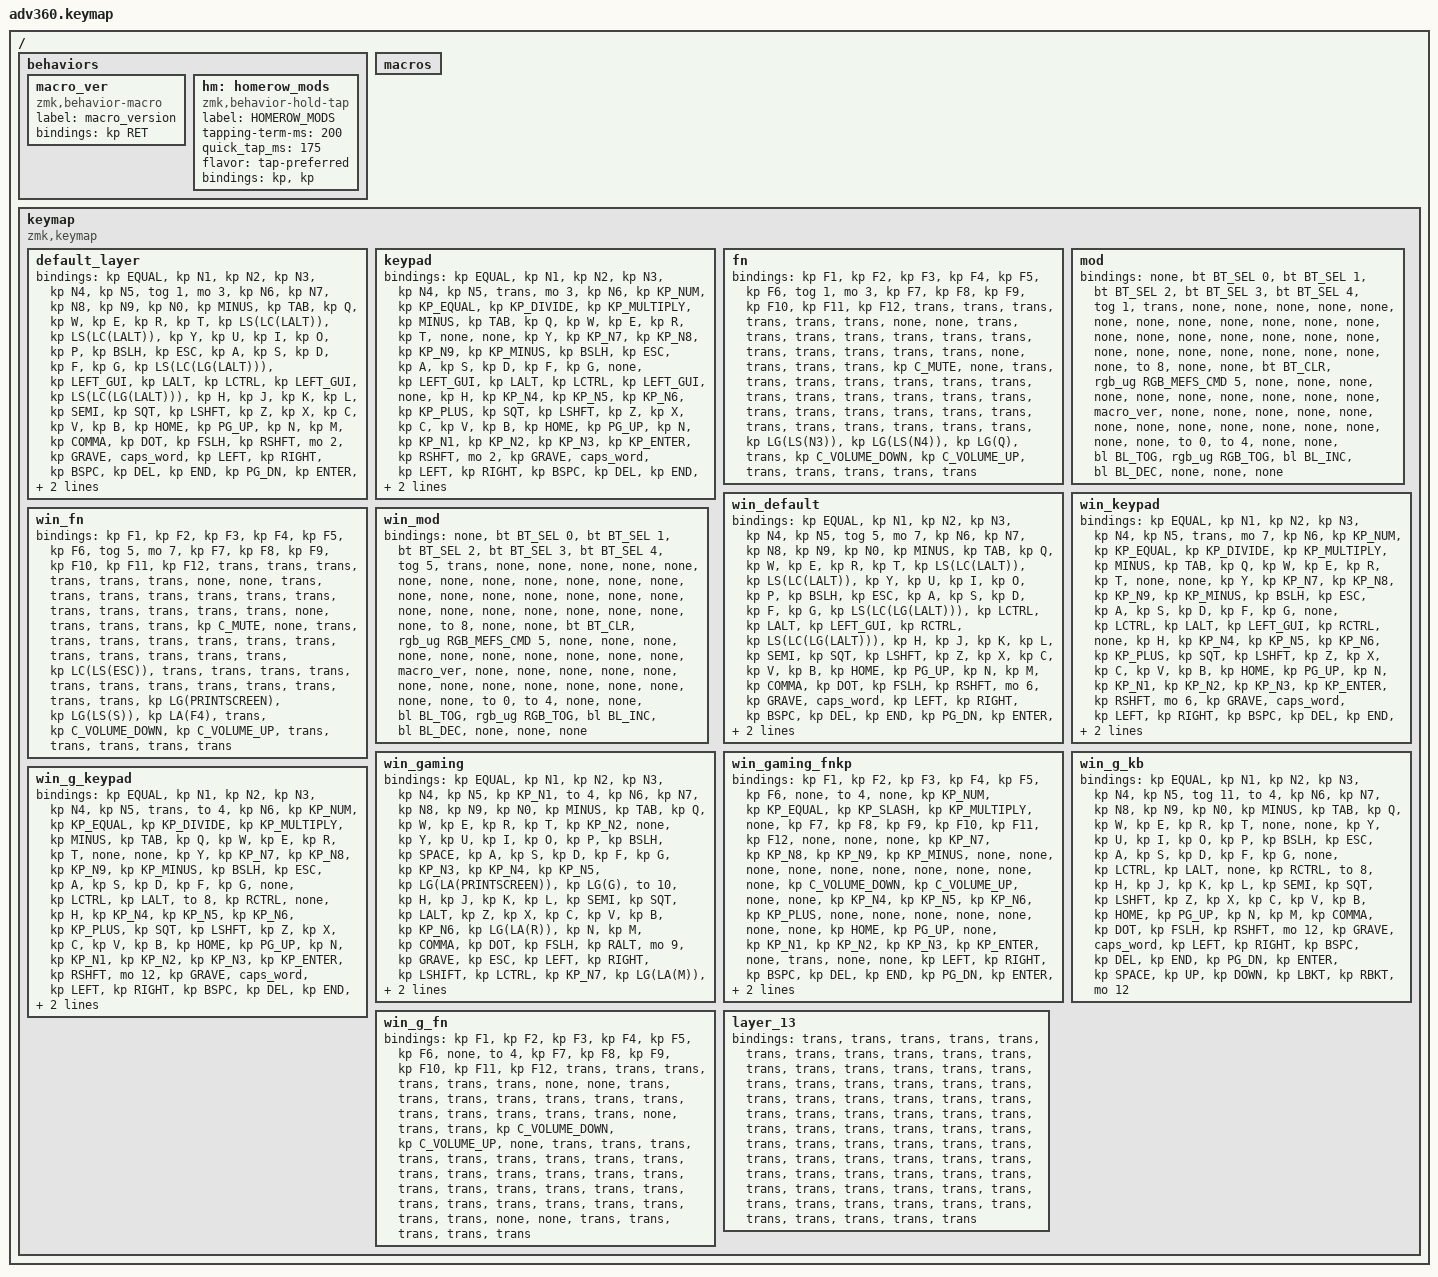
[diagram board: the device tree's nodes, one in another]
#include <behaviors.dtsi>
#include <dt-bindings/zmk/backlight.h>
#include <dt-bindings/zmk/bt.h>
#include <dt-bindings/zmk/keys.h>
#include <dt-bindings/zmk/rgb.h>

/ {
    behaviors {
        #include "macros.dtsi"
      #include "version.dtsi"
      #ifndef VERSION_MACRO

        macro_ver: macro_ver {
            compatible = "zmk,behavior-macro";
            label = "macro_version";
            #binding-cells = <0>;
            bindings = <&kp RET>;
        };

        #endif

        hm: homerow_mods {
            compatible = "zmk,behavior-hold-tap";
            label = "HOMEROW_MODS";
            #binding-cells = <2>;
            tapping-term-ms = <200>;
            quick_tap_ms = <175>;
            flavor = "tap-preferred";
            bindings = <&kp>, <&kp>;
        };
    };

    macros {
    };

    keymap {
        compatible = "zmk,keymap";

        default_layer {
            bindings = <
&kp EQUAL  &kp N1     &kp N2      &kp N3    &kp N4     &kp N5  &tog 1                                                                     &mo 3                 &kp N6  &kp N7  &kp N8     &kp N9    &kp N0    &kp MINUS
&kp TAB    &kp Q      &kp W       &kp E     &kp R      &kp T   &kp LS(LC(LALT))                                                           &kp LS(LC(LALT))      &kp Y   &kp U   &kp I      &kp O     &kp P     &kp BSLH
&kp ESC    &kp A      &kp S       &kp D     &kp F      &kp G   &kp LS(LC(LG(LALT)))  &kp LEFT_GUI  &kp LALT      &kp LCTRL  &kp LEFT_GUI  &kp LS(LC(LG(LALT)))  &kp H   &kp J   &kp K      &kp L     &kp SEMI  &kp SQT
&kp LSHFT  &kp Z      &kp X       &kp C     &kp V      &kp B                                       &kp HOME      &kp PG_UP                                      &kp N   &kp M   &kp COMMA  &kp DOT   &kp FSLH  &kp RSHFT
&mo 2      &kp GRAVE  &caps_word  &kp LEFT  &kp RIGHT          &kp BSPC              &kp DEL       &kp END       &kp PG_DN  &kp ENTER     &kp SPACE                     &kp UP  &kp DOWN   &kp LBKT  &kp RBKT  &mo 2
            >;
        };

        keypad {
            bindings = <
&kp EQUAL  &kp N1     &kp N2      &kp N3    &kp N4     &kp N5  &trans                                                         &mo 3      &kp N6  &kp KP_NUM  &kp KP_EQUAL  &kp KP_DIVIDE  &kp KP_MULTIPLY  &kp MINUS
&kp TAB    &kp Q      &kp W       &kp E     &kp R      &kp T   &none                                                          &none      &kp Y   &kp KP_N7   &kp KP_N8     &kp KP_N9      &kp KP_MINUS     &kp BSLH
&kp ESC    &kp A      &kp S       &kp D     &kp F      &kp G   &none     &kp LEFT_GUI  &kp LALT      &kp LCTRL  &kp LEFT_GUI  &none      &kp H   &kp KP_N4   &kp KP_N5     &kp KP_N6      &kp KP_PLUS      &kp SQT
&kp LSHFT  &kp Z      &kp X       &kp C     &kp V      &kp B                           &kp HOME      &kp PG_UP                           &kp N   &kp KP_N1   &kp KP_N2     &kp KP_N3      &kp KP_ENTER     &kp RSHFT
&mo 2      &kp GRAVE  &caps_word  &kp LEFT  &kp RIGHT          &kp BSPC  &kp DEL       &kp END       &kp PG_DN  &kp ENTER     &kp KP_N0          &kp UP      &kp DOWN      &kp KP_DOT     &kp RBKT         &mo 2
            >;
        };

        fn {
            bindings = <
&kp F1  &kp F2  &kp F3  &kp F4  &kp F5  &kp F6  &tog 1                                                                    &mo 3            &kp F7  &kp F8  &kp F9  &kp F10  &kp F11  &kp F12
&trans  &trans  &trans  &trans  &trans  &trans  &none                                                                     &none            &trans  &trans  &trans  &trans   &trans   &trans
&trans  &trans  &trans  &trans  &trans  &trans  &none           &trans          &trans         &trans  &kp C_MUTE         &none            &trans  &trans  &trans  &trans   &trans   &trans
&trans  &trans  &trans  &trans  &trans  &trans                                  &trans         &trans                                      &trans  &trans  &trans  &trans   &trans   &trans
&trans  &trans  &trans  &trans  &trans          &kp LG(LS(N3))  &kp LG(LS(N4))  &kp LG(Q)      &trans  &kp C_VOLUME_DOWN  &kp C_VOLUME_UP          &trans  &trans  &trans   &trans   &trans
            >;
        };

        mod {
            bindings = <
&none  &bt BT_SEL 0  &bt BT_SEL 1  &bt BT_SEL 2  &bt BT_SEL 3  &bt BT_SEL 4  &tog 1                                       &trans                  &none  &none       &none       &none  &none  &none
&none  &none         &none         &none         &none         &none         &none                                        &none                   &none  &none       &none       &none  &none  &none
&none  &none         &none         &none         &none         &none         &none   &to 8  &none      &none  &bt BT_CLR  &rgb_ug RGB_MEFS_CMD 5  &none  &none       &none       &none  &none  &none
&none  &none         &none         &none         &macro_ver    &none                        &none      &none                                      &none  &none       &none       &none  &none  &none
&none  &none         &none         &none         &none                       &to 0   &to 4  &none      &none  &bl BL_TOG  &rgb_ug RGB_TOG                &bl BL_INC  &bl BL_DEC  &none  &none  &none
            >;
        };

        win_default {
            bindings = <
&kp EQUAL  &kp N1     &kp N2      &kp N3    &kp N4     &kp N5  &tog 5                                                                  &mo 7                 &kp N6  &kp N7  &kp N8     &kp N9    &kp N0    &kp MINUS
&kp TAB    &kp Q      &kp W       &kp E     &kp R      &kp T   &kp LS(LC(LALT))                                                        &kp LS(LC(LALT))      &kp Y   &kp U   &kp I      &kp O     &kp P     &kp BSLH
&kp ESC    &kp A      &kp S       &kp D     &kp F      &kp G   &kp LS(LC(LG(LALT)))  &kp LCTRL  &kp LALT      &kp LEFT_GUI  &kp RCTRL  &kp LS(LC(LG(LALT)))  &kp H   &kp J   &kp K      &kp L     &kp SEMI  &kp SQT
&kp LSHFT  &kp Z      &kp X       &kp C     &kp V      &kp B                                    &kp HOME      &kp PG_UP                                      &kp N   &kp M   &kp COMMA  &kp DOT   &kp FSLH  &kp RSHFT
&mo 6      &kp GRAVE  &caps_word  &kp LEFT  &kp RIGHT          &kp BSPC              &kp DEL    &kp END       &kp PG_DN     &kp ENTER  &kp SPACE                     &kp UP  &kp DOWN   &kp LBKT  &kp RBKT  &mo 6
            >;
        };

        win_keypad {
            bindings = <
&kp EQUAL  &kp N1     &kp N2      &kp N3    &kp N4     &kp N5  &trans                                                      &mo 7      &kp N6  &kp KP_NUM  &kp KP_EQUAL  &kp KP_DIVIDE  &kp KP_MULTIPLY  &kp MINUS
&kp TAB    &kp Q      &kp W       &kp E     &kp R      &kp T   &none                                                       &none      &kp Y   &kp KP_N7   &kp KP_N8     &kp KP_N9      &kp KP_MINUS     &kp BSLH
&kp ESC    &kp A      &kp S       &kp D     &kp F      &kp G   &none     &kp LCTRL  &kp LALT      &kp LEFT_GUI  &kp RCTRL  &none      &kp H   &kp KP_N4   &kp KP_N5     &kp KP_N6      &kp KP_PLUS      &kp SQT
&kp LSHFT  &kp Z      &kp X       &kp C     &kp V      &kp B                        &kp HOME      &kp PG_UP                           &kp N   &kp KP_N1   &kp KP_N2     &kp KP_N3      &kp KP_ENTER     &kp RSHFT
&mo 6      &kp GRAVE  &caps_word  &kp LEFT  &kp RIGHT          &kp BSPC  &kp DEL    &kp END       &kp PG_DN     &kp ENTER  &kp KP_N0          &kp UP      &kp DOWN      &kp KP_DOT     &kp RBKT         &mo 6
            >;
        };

        win_fn {
            bindings = <
&kp F1  &kp F2  &kp F3  &kp F4  &kp F5  &kp F6  &tog 5                                                                              &mo 7            &kp F7  &kp F8  &kp F9  &kp F10  &kp F11  &kp F12
&trans  &trans  &trans  &trans  &trans  &trans  &none                                                                               &none            &trans  &trans  &trans  &trans   &trans   &trans
&trans  &trans  &trans  &trans  &trans  &trans  &none                &trans         &trans               &trans  &kp C_MUTE         &none            &trans  &trans  &trans  &trans   &trans   &trans
&trans  &trans  &trans  &trans  &trans  &trans                                      &kp LC(LS(ESC))      &trans                                      &trans  &trans  &trans  &trans   &trans   &trans
&trans  &trans  &trans  &trans  &trans          &kp LG(PRINTSCREEN)  &kp LG(LS(S))  &kp LA(F4)           &trans  &kp C_VOLUME_DOWN  &kp C_VOLUME_UP          &trans  &trans  &trans   &trans   &trans
            >;
        };

        win_mod {
            bindings = <
&none  &bt BT_SEL 0  &bt BT_SEL 1  &bt BT_SEL 2  &bt BT_SEL 3  &bt BT_SEL 4  &tog 5                                       &trans                  &none  &none       &none       &none  &none  &none
&none  &none         &none         &none         &none         &none         &none                                        &none                   &none  &none       &none       &none  &none  &none
&none  &none         &none         &none         &none         &none         &none   &to 8  &none      &none  &bt BT_CLR  &rgb_ug RGB_MEFS_CMD 5  &none  &none       &none       &none  &none  &none
&none  &none         &none         &none         &macro_ver    &none                        &none      &none                                      &none  &none       &none       &none  &none  &none
&none  &none         &none         &none         &none                       &to 0   &to 4  &none      &none  &bl BL_TOG  &rgb_ug RGB_TOG                &bl BL_INC  &bl BL_DEC  &none  &none  &none
            >;
        };

        win_gaming {
            bindings = <
&kp EQUAL  &kp N1     &kp N2   &kp N3    &kp N4     &kp N5  &kp KP_N1                                                                 &to 4       &kp N6  &kp N7  &kp N8     &kp N9    &kp N0    &kp MINUS
&kp TAB    &kp Q      &kp W    &kp E     &kp R      &kp T   &kp KP_N2                                                                 &none       &kp Y   &kp U   &kp I      &kp O     &kp P     &kp BSLH
&kp SPACE  &kp A      &kp S    &kp D     &kp F      &kp G   &kp KP_N3   &kp KP_N4  &kp KP_N5      &kp LG(LA(PRINTSCREEN))  &kp LG(G)  &to 10      &kp H   &kp J   &kp K      &kp L     &kp SEMI  &kp SQT
&kp LALT   &kp Z      &kp X    &kp C     &kp V      &kp B                          &kp KP_N6      &kp LG(LA(R))                                   &kp N   &kp M   &kp COMMA  &kp DOT   &kp FSLH  &kp RALT
&mo 9      &kp GRAVE  &kp ESC  &kp LEFT  &kp RIGHT          &kp LSHIFT  &kp LCTRL  &kp KP_N7      &kp LG(LA(M))            &kp RCTRL  &kp RSHIFT          &kp UP  &kp DOWN   &kp LBKT  &kp RBKT  &mo 9
            >;
        };

        win_gaming_fnkp {
            bindings = <
&kp F1  &kp F2  &kp F3  &kp F4    &kp F5     &kp F6   &none                                                                &to 4      &none  &kp KP_NUM  &kp KP_EQUAL  &kp KP_SLASH  &kp KP_MULTIPLY  &none
&kp F7  &kp F8  &kp F9  &kp F10   &kp F11    &kp F12  &none                                                                &none      &none  &kp KP_N7   &kp KP_N8     &kp KP_N9     &kp KP_MINUS     &none
&none   &none   &none   &none     &none      &none    &none     &none    &none         &kp C_VOLUME_DOWN  &kp C_VOLUME_UP  &none      &none  &kp KP_N4   &kp KP_N5     &kp KP_N6     &kp KP_PLUS      &none
&none   &none   &none   &none     &none      &none                       &kp HOME      &kp PG_UP                                      &none  &kp KP_N1   &kp KP_N2     &kp KP_N3     &kp KP_ENTER     &none
&trans  &none   &none   &kp LEFT  &kp RIGHT           &kp BSPC  &kp DEL  &kp END       &kp PG_DN          &kp ENTER        &kp KP_N0         &kp UP      &kp DOWN      &kp KP_DOT    &none            &trans
            >;
        };

        win_g_kb {
            bindings = <
&kp EQUAL  &kp N1     &kp N2      &kp N3    &kp N4     &kp N5  &tog 11                                                  &to 4      &kp N6  &kp N7  &kp N8     &kp N9    &kp N0    &kp MINUS
&kp TAB    &kp Q      &kp W       &kp E     &kp R      &kp T   &none                                                    &none      &kp Y   &kp U   &kp I      &kp O     &kp P     &kp BSLH
&kp ESC    &kp A      &kp S       &kp D     &kp F      &kp G   &none     &kp LCTRL  &kp LALT      &none      &kp RCTRL  &to 8      &kp H   &kp J   &kp K      &kp L     &kp SEMI  &kp SQT
&kp LSHFT  &kp Z      &kp X       &kp C     &kp V      &kp B                        &kp HOME      &kp PG_UP                        &kp N   &kp M   &kp COMMA  &kp DOT   &kp FSLH  &kp RSHFT
&mo 12     &kp GRAVE  &caps_word  &kp LEFT  &kp RIGHT          &kp BSPC  &kp DEL    &kp END       &kp PG_DN  &kp ENTER  &kp SPACE          &kp UP  &kp DOWN   &kp LBKT  &kp RBKT  &mo 12
            >;
        };

        win_g_keypad {
            bindings = <
&kp EQUAL  &kp N1     &kp N2      &kp N3    &kp N4     &kp N5  &trans                                                   &to 4      &kp N6  &kp KP_NUM  &kp KP_EQUAL  &kp KP_DIVIDE  &kp KP_MULTIPLY  &kp MINUS
&kp TAB    &kp Q      &kp W       &kp E     &kp R      &kp T   &none                                                    &none      &kp Y   &kp KP_N7   &kp KP_N8     &kp KP_N9      &kp KP_MINUS     &kp BSLH
&kp ESC    &kp A      &kp S       &kp D     &kp F      &kp G   &none     &kp LCTRL  &kp LALT      &to 8      &kp RCTRL  &none      &kp H   &kp KP_N4   &kp KP_N5     &kp KP_N6      &kp KP_PLUS      &kp SQT
&kp LSHFT  &kp Z      &kp X       &kp C     &kp V      &kp B                        &kp HOME      &kp PG_UP                        &kp N   &kp KP_N1   &kp KP_N2     &kp KP_N3      &kp KP_ENTER     &kp RSHFT
&mo 12     &kp GRAVE  &caps_word  &kp LEFT  &kp RIGHT          &kp BSPC  &kp DEL    &kp END       &kp PG_DN  &kp ENTER  &kp KP_N0          &kp UP      &kp DOWN      &kp KP_DOT     &kp RBKT         &mo 12
            >;
        };

        win_g_fn {
            bindings = <
&kp F1  &kp F2  &kp F3  &kp F4  &kp F5  &kp F6  &none                                                           &to 4  &kp F7  &kp F8  &kp F9  &kp F10  &kp F11  &kp F12
&trans  &trans  &trans  &trans  &trans  &trans  &none                                                           &none  &trans  &trans  &trans  &trans   &trans   &trans
&trans  &trans  &trans  &trans  &trans  &trans  &none   &trans  &trans      &kp C_VOLUME_DOWN  &kp C_VOLUME_UP  &none  &trans  &trans  &trans  &trans   &trans   &trans
&trans  &trans  &trans  &trans  &trans  &trans                  &trans      &trans                                     &trans  &trans  &trans  &trans   &trans   &trans
&trans  &trans  &trans  &trans  &trans          &trans  &trans  &trans      &trans             &none            &none          &trans  &trans  &trans   &trans   &trans
            >;
        };

        layer_13 {
            bindings = <
&trans  &trans  &trans  &trans  &trans  &trans  &trans                                      &trans  &trans  &trans  &trans  &trans  &trans  &trans
&trans  &trans  &trans  &trans  &trans  &trans  &trans                                      &trans  &trans  &trans  &trans  &trans  &trans  &trans
&trans  &trans  &trans  &trans  &trans  &trans  &trans  &trans  &trans      &trans  &trans  &trans  &trans  &trans  &trans  &trans  &trans  &trans
&trans  &trans  &trans  &trans  &trans  &trans                  &trans      &trans                  &trans  &trans  &trans  &trans  &trans  &trans
&trans  &trans  &trans  &trans  &trans          &trans  &trans  &trans      &trans  &trans  &trans          &trans  &trans  &trans  &trans  &trans
            >;
        };
    };
};
